# ATA5700M322 device description
Architecture: AVR8; Family: megaAVR
Registers are 8-bit, access not given, no defined reset value unless marked. A register's access mark holds for its fields unless they carry their own. Offsets are from the block's base; [hi:lo] are bit positions.

## TIMER0_WDT
Instances: TIMER0_WDT 0x00
0x52 T0IFR — Timer0 Interrupt Flag Register
  [0] T0F — Timer0 Flag
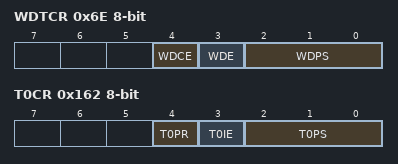
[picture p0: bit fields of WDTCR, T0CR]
0x6E WDTCR — Watchdog Timer0 control Register
  [4] WDCE — Watchdog Change Enable
  [3] WDE — Watchdog System Reset Enable
  [2:0] WDPS — Watchdog Prescaler Select
    0=1ms typ (0.85ms min); 1=4ms typ (3.4ms min); 2=32ms typ (27ms min); 3=2.1s typ (1.75s min); 4=4.2s typ (3.5s min); 5=16.8s typ (14s min); 6=134s typ (110s min); 7=268s typ (220s min)
0x162 T0CR — Timer0 Control Register
  [4] T0PR — Timer0 Prescaler Reset
  [3] T0IE — Timer0 Interrupt Enable
  [2:0] T0PS — Timer0 Prescaler Select
    0=0.256ms typ; 1=1ms typ; 2=8ms typ; 3=0.5s typ; 4=1s typ; 5=8s typ; 6=67s typ; 7=134s typ

## TIMER1
Instances: TIMER1 0x00
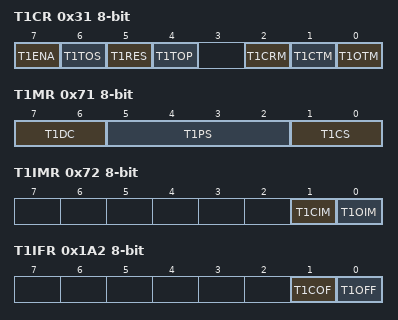
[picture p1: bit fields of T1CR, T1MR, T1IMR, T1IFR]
0x31 T1CR — Timer1 control Register
  [7] T1ENA — Timer1 Enable
  [6] T1TOS — Timer1 Toggle with Start
  [5] T1RES — Timer1 Reset
  [4] T1TOP — Timer1 Toggle Output Preset
  [2] T1CRM — Timer1 Compare Reset Mask
  [1] T1CTM — Timer1 Compare Toggle Mask
  [0] T1OTM — Timer1 Overflow Toggle Mask
0x6F T1CNT — Timer1 Counter Register
0x70 T1COR — Timer1 Compare Register
0x71 T1MR — Timer1 Mode Register
  [7:6] T1DC — Timer1 Duty Cycle
    0=Bypass; 1=Duty cycle 1/1 (div 2); 2=Duty cycle 1/2 (div 3); 3=Duty cycle 1/3 (div 4)
  [5:2] T1PS — Timer1 Prescaler Select
  [1:0] T1CS — Timer1 Clock Select
    0=clk_src; 1=clk_frc; 2=clk_T; 3=clk_mrc
0x72 T1IMR — Timer1 Interrupt Mask Register
  [1] T1CIM — Timer1 Compare Interrupt Mask
  [0] T1OIM — Timer1 Overflow Interrupt Mask
0x1A2 T1IFR — Timer1 Interrupt Flag Register
  [1] T1COF — Timer1 Compare Flag
  [0] T1OFF — Timer1 Overflow Flag

## TIMER2
Instances: TIMER2 0x00
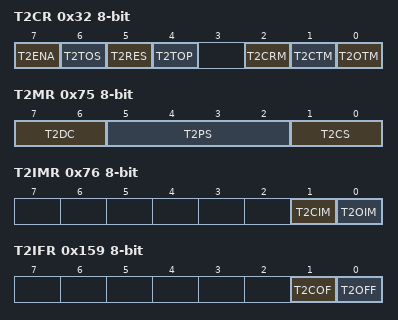
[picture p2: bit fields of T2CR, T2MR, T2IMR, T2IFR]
0x32 T2CR — Timer2 Control Register
  [7] T2ENA — Timer2 Enable
  [6] T2TOS — Timer2 Toggle with Start
  [5] T2RES — Timer2 Reset
  [4] T2TOP — Timer2 Toggle Output Preset
  [2] T2CRM — Timer2 Compare Reset Mask
  [1] T2CTM — Timer2 Compare Toggle Mask
  [0] T2OTM — Timer2 Overflow Toggle Mask
0x73 T2CNT — Timer2 Counter Register
0x74 T2COR — Timer2 Compare Register
0x75 T2MR — Timer2 Mode Register
  [7:6] T2DC — Timer2 Duty Cycle
    0=Bypass; 1=Duty cycle 1/1 (div 2); 2=Duty cycle 1/2 (div 3); 3=Duty cycle 1/3 (div 4)
  [5:2] T2PS — Timer2 Prescaler Select
  [1:0] T2CS — Timer2 Clock Select
    0=clk_src; 1=clk_mrc; 2=clk_T; 3=clk_xto4
0x76 T2IMR — Timer2 Interrupt Mask Register
  [1] T2CIM — Timer2 Compare Interrupt Mask
  [0] T2OIM — Timer2 Overflow Interrupt Mask
0x159 T2IFR — Timer2 Interrupt Flag Register
  [1] T2COF — Timer2 Compare Flag
  [0] T2OFF — Timer2 Overflow Flag

## TIMER3
Instances: TIMER3 0x00
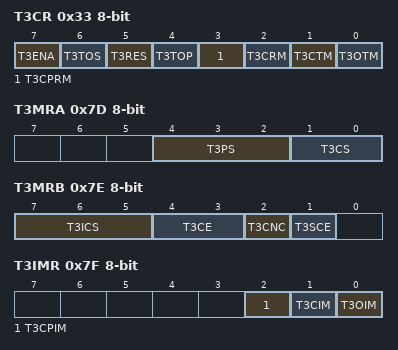
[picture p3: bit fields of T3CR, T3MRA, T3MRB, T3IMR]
0x33 T3CR — Timer3 control Register
  [7] T3ENA — Timer3 Enable
  [6] T3TOS — Timer3 Toggle with Start
  [5] T3RES — Timer3 Reset
  [4] T3TOP — Timer3 Toggle Output Preset
  [3] T3CPRM — Timer3 CaPture Reset Mask
  [2] T3CRM — Timer3 Compare Reset Mask
  [1] T3CTM — Timer3 Compare Toggle Mask
  [0] T3OTM — Timer3 Overflow Toggle Mask
0x77 T3CNT 16-bit — Timer3 counter Register
0x79 T3COR 16-bit — Timer3 compare Register
0x7B T3ICR 16-bit — Timer3 input capture Register
0x7D T3MRA — Timer3 mode Register
  [4:2] T3PS — Timer3 Prescaler Select
  [1:0] T3CS — Timer3 Clock Select
    0=clk_frc; 1=clk_T; 2=clk_xto4; 3=clk_TEI
0x7E T3MRB — Timer3 mode Register
  [7:5] T3ICS — Timer3 Input Capture Select
    0=clk_T2; 1=clk_T1; 2=clk_T4; 3=TICP; 4=LFES; 5=clk_src; 6=TPGAP
  [4:3] T3CE — Timer3 Capture Edge select
    0=disable; 1=rising edge; 2=falling edge; 3=both edges
  [2] T3CNC — Timer3 input Capture Noise Canceller
  [1] T3SCE — Timer3 Software Capture Enable
0x7F T3IMR — Timer3 interrupt mask Register
  [2] T3CPIM — Timer3 Capture Interrupt Mask
  [1] T3CIM — Timer3 Compare Interrupt Mask
  [0] T3OIM — Timer3 Overflow Interrupt Mask
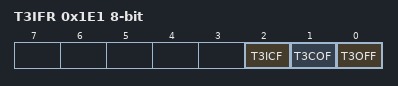
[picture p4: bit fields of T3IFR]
0x1E1 T3IFR — Timer3 interrupt flag Register
  [2] T3ICF — Timer3 Input Capture Flag
  [1] T3COF — Timer3 Compare Flag
  [0] T3OFF — Timer3 OverFlow Flag
